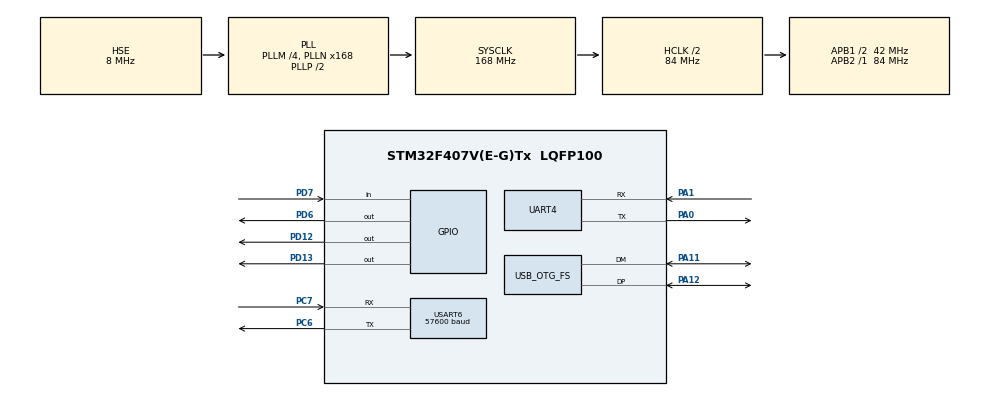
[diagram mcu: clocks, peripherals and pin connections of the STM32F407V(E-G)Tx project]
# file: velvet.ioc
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Mcu.Family=STM32F4
Mcu.Name=STM32F407V(E-G)Tx
Mcu.Package=LQFP100
NVIC.OTG_FS_IRQn=true\:0\:0\:false\:false\:true\:false\:true\:true
NVIC.PriorityGroup=NVIC_PRIORITYGROUP_4
PA0-WKUP.Mode=Asynchronous
PA0-WKUP.Signal=UART4_TX
PA1.Mode=Asynchronous
PA1.Signal=UART4_RX
PA11.Mode=Device_Only
PA11.Signal=USB_OTG_FS_DM
PA12.Mode=Device_Only
PA12.Signal=USB_OTG_FS_DP
PC6.Mode=Asynchronous
PC6.Signal=USART6_TX
PC7.Mode=Asynchronous
PC7.Signal=USART6_RX
PD12.Signal=GPIO_Output
PD13.Signal=GPIO_Output
PD6.Signal=GPIO_Output
PD7.Signal=GPIO_Input
PH0-OSC_IN.Mode=HSE-External-Oscillator
PH0-OSC_IN.Signal=RCC_OSC_IN
PH1-OSC_OUT.Mode=HSE-External-Oscillator
PH1-OSC_OUT.Signal=RCC_OSC_OUT
ProjectManager.HeapSize=0x200
ProjectManager.StackSize=0x400
ProjectManager.TargetToolchain=Makefile
RCC.48MHZClocksFreq_Value=48000000
RCC.AHBCLKDivider=RCC_SYSCLK_DIV2
RCC.AHBFreq_Value=84000000
RCC.APB1CLKDivider=RCC_HCLK_DIV2
RCC.APB1Freq_Value=42000000
RCC.APB1TimFreq_Value=84000000
RCC.APB2Freq_Value=84000000
RCC.APB2TimFreq_Value=84000000
RCC.CortexFreq_Value=84000000
RCC.HCLKFreq_Value=84000000
RCC.HSE_VALUE=8000000
RCC.HSI_VALUE=16000000
RCC.LSE_VALUE=32768
RCC.PLLM=4
RCC.PLLN=168
RCC.PLLQ=7
RCC.SYSCLKFreq_VALUE=168000000
RCC.SYSCLKSource=RCC_SYSCLKSOURCE_PLLCLK
RCC.VCOOutputFreq_Value=336000000
UART4.VirtualMode=Asynchronous
USART6.BaudRate=57600
USART6.VirtualMode=VM_ASYNC
USB_DEVICE.CLASS_NAME_FS=CDC
USB_DEVICE.VirtualMode-CDC_FS=Cdc
USB_DEVICE.VirtualModeFS=Cdc_FS
USB_OTG_FS.VirtualMode=Device_Only
VP_USB_DEVICE_VS_USB_DEVICE_CDC_FS.Mode=CDC_FS
board=custom

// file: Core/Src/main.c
/* USER CODE BEGIN Header */
/**
  ******************************************************************************
  * @file           : main.c
  * @brief          : Main program body
  ******************************************************************************
  * @attention
  *
  * Copyright (c) 2022 STMicroelectronics.
  * All rights reserved.
  *
  * This software is licensed under terms that can be found in the LICENSE file
  * in the root directory of this software component.
  * If no LICENSE file comes with this software, it is provided AS-IS.
  *
  ******************************************************************************
  */
/* USER CODE END Header */
#include "main.h"
#include "usb_device.h"

/* USER CODE BEGIN Includes */
#include "adc.h"
#include "rfid.h"
#include <string.h>
#include <stdbool.h>
#include "usb.h"
/* USER CODE END Includes */

/* USER CODE BEGIN PTD */
struct CowData {
    uint8_t id[50];
    uint8_t idLength;
    uint16_t weight;
    unsigned long timestamp;
};
/* USER CODE END PTD */

UART_HandleTypeDef huart4;
UART_HandleTypeDef huart6;

void SystemClock_Config(void);
static void MX_GPIO_Init(void);
static void MX_USART6_UART_Init(void);
static void MX_UART4_Init(void);
/* USER CODE BEGIN PFP */
// void USBPrint(uint8_t *buf);
// void USBprintArray(uint8_t *buf, uint8_t size);

/* USER CODE END PFP */

int main(void)
{
  /* USER CODE BEGIN 1 */

  // struct TagData tagNum;
  // uint8_t out[50];
	// uint16_t weight;

  /* USER CODE END 1 */

  /* MCU Configuration--------------------------------------------------------*/

  /* Reset of all peripherals, Initializes the Flash interface and the Systick. */
  HAL_Init();

  /* Configure the system clock */
  SystemClock_Config();

  /* Initialize all configured peripherals */
  MX_GPIO_Init();
  MX_USART6_UART_Init();
  MX_USB_DEVICE_Init();
  MX_UART4_Init();
  /* USER CODE BEGIN 2 */

  ScalesCalibrate();  // calibrate scale

  /* USER CODE END 2 */

  /* Infinite loop */
  /* USER CODE BEGIN WHILE */
  // uint8_t out[3] = {0x03, 0x07, 0x0A};
	while (1){

    // HAL_GPIO_WritePin(GPIOD, GPIO_PIN_12, GPIO_PIN_RESET);
		// weight = GetAnimalWight();
		// if(weight >= 100){
		// 	resetTagData(&tagNum);
		// 	bool TagReadStatus = RFIDReadTag(&huart6, &tagNum);
		// 	if (TagReadStatus) {

		// 	}
		// }

		// USBPrint("--- START APP ---\n");
		// // bool status = RFIDReadTag(&huart6, &tagNum);
		// // unsigned long temp = HX711_Read();
		// // if
		// sprintf(out, "ADC VAL: %lu\n", HX711_Read());
		// USBPrint(out);
		// // if (status){
		// //     USBPrint("RESP: ");
		// //     USBprintArray(tagNum.id, tagNum.length);
		// // } else {
		// // 	USBPrint("READ FALSE or NO TAG\n");
		// // }
		// USBPrint("*** END ***\n");
		// CDC_Transmit_FS("ENDCCCC\r\n", 9);

		HAL_Delay(2000);
    /* USER CODE END WHILE */

	}
}

void SystemClock_Config(void)
{
  RCC_OscInitTypeDef RCC_OscInitStruct = {0};
  RCC_ClkInitTypeDef RCC_ClkInitStruct = {0};

  /** Configure the main internal regulator output voltage
  */
  __HAL_RCC_PWR_CLK_ENABLE();
  __HAL_PWR_VOLTAGESCALING_CONFIG(PWR_REGULATOR_VOLTAGE_SCALE1);

  /** Initializes the RCC Oscillators according to the specified parameters
  * in the RCC_OscInitTypeDef structure.
  */
  RCC_OscInitStruct.OscillatorType = RCC_OSCILLATORTYPE_HSE;
  RCC_OscInitStruct.HSEState = RCC_HSE_ON;
  RCC_OscInitStruct.PLL.PLLState = RCC_PLL_ON;
  RCC_OscInitStruct.PLL.PLLSource = RCC_PLLSOURCE_HSE;
  RCC_OscInitStruct.PLL.PLLM = 4;
  RCC_OscInitStruct.PLL.PLLN = 168;
  RCC_OscInitStruct.PLL.PLLP = RCC_PLLP_DIV2;
  RCC_OscInitStruct.PLL.PLLQ = 7;
  if (HAL_RCC_OscConfig(&RCC_OscInitStruct) != HAL_OK)
  {
    Error_Handler();
  }

  /** Initializes the CPU, AHB and APB buses clocks
  */
  RCC_ClkInitStruct.ClockType = RCC_CLOCKTYPE_HCLK|RCC_CLOCKTYPE_SYSCLK
                              |RCC_CLOCKTYPE_PCLK1|RCC_CLOCKTYPE_PCLK2;
  RCC_ClkInitStruct.SYSCLKSource = RCC_SYSCLKSOURCE_PLLCLK;
  RCC_ClkInitStruct.AHBCLKDivider = RCC_SYSCLK_DIV2;
  RCC_ClkInitStruct.APB1CLKDivider = RCC_HCLK_DIV2;
  RCC_ClkInitStruct.APB2CLKDivider = RCC_HCLK_DIV1;

  if (HAL_RCC_ClockConfig(&RCC_ClkInitStruct, FLASH_LATENCY_2) != HAL_OK)
  {
    Error_Handler();
  }
}

static void MX_UART4_Init(void)
{

  huart4.Instance = UART4;
  huart4.Init.BaudRate = 115200;
  huart4.Init.WordLength = UART_WORDLENGTH_8B;
  huart4.Init.StopBits = UART_STOPBITS_1;
  huart4.Init.Parity = UART_PARITY_NONE;
  huart4.Init.Mode = UART_MODE_TX_RX;
  huart4.Init.HwFlowCtl = UART_HWCONTROL_NONE;
  huart4.Init.OverSampling = UART_OVERSAMPLING_16;
  if (HAL_UART_Init(&huart4) != HAL_OK)
  {
    Error_Handler();
  }

}

static void MX_USART6_UART_Init(void)
{

  huart6.Instance = USART6;
  huart6.Init.BaudRate = 57600;
  huart6.Init.WordLength = UART_WORDLENGTH_8B;
  huart6.Init.StopBits = UART_STOPBITS_1;
  huart6.Init.Parity = UART_PARITY_NONE;
  huart6.Init.Mode = UART_MODE_TX_RX;
  huart6.Init.HwFlowCtl = UART_HWCONTROL_NONE;
  huart6.Init.OverSampling = UART_OVERSAMPLING_16;
  if (HAL_UART_Init(&huart6) != HAL_OK)
  {
    Error_Handler();
  }

}

static void MX_GPIO_Init(void)
{
  GPIO_InitTypeDef GPIO_InitStruct = {0};

  /* GPIO Ports Clock Enable */
  __HAL_RCC_GPIOH_CLK_ENABLE();
  __HAL_RCC_GPIOA_CLK_ENABLE();
  __HAL_RCC_GPIOD_CLK_ENABLE();
  __HAL_RCC_GPIOC_CLK_ENABLE();

  /*Configure GPIO pin Output Level */
  HAL_GPIO_WritePin(GPIOD, GPIO_PIN_12|GPIO_PIN_13|GPIO_PIN_6, GPIO_PIN_RESET);

  /*Configure GPIO pins : PD12 PD13 PD6 */
  GPIO_InitStruct.Pin = GPIO_PIN_12|GPIO_PIN_13|GPIO_PIN_6;
  GPIO_InitStruct.Mode = GPIO_MODE_OUTPUT_PP;
  GPIO_InitStruct.Pull = GPIO_NOPULL;
  GPIO_InitStruct.Speed = GPIO_SPEED_FREQ_LOW;
  HAL_GPIO_Init(GPIOD, &GPIO_InitStruct);

  /*Configure GPIO pin : PD7 */
  GPIO_InitStruct.Pin = GPIO_PIN_7;
  GPIO_InitStruct.Mode = GPIO_MODE_INPUT;
  GPIO_InitStruct.Pull = GPIO_NOPULL;
  HAL_GPIO_Init(GPIOD, &GPIO_InitStruct);

}

/* USER CODE BEGIN 4 */
// void USBPrint(uint8_t *buf)
// {
//   HAL_Delay(50);
//   CDC_Transmit_FS(buf, strlen(buf));
// }

// void USBprintArray(uint8_t *buf, uint8_t size){
//   uint8_t out[10];
//   USBPrint("[");
//   for(int i = 0; i < size; ++i){
//     sprintf(out, "%X, ", buf[i]);
//     USBPrint(out);
//   }
//   USBPrint("]\n");
// }
/* USER CODE END 4 */

void Error_Handler(void)
{
  __disable_irq();
  while (1)
  {
  }
}
